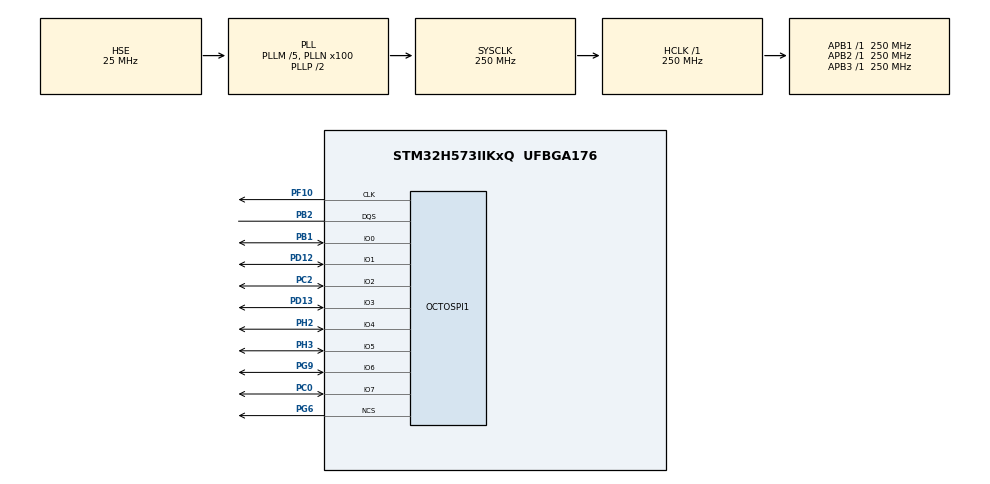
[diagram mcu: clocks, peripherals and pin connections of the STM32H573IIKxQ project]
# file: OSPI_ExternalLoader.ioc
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CORTEX_M33_NS.userName=CORTEX_M33
Mcu.Family=STM32H5
Mcu.Name=STM32H573IIKxQ
Mcu.Package=UFBGA176
NVIC.OCTOSPI1_IRQn=true\:0\:0\:false\:false\:true\:true\:true\:true
NVIC.PriorityGroup=NVIC_PRIORITYGROUP_4
OCTOSPI1.ChipSelectHighTimeCycle=1
OCTOSPI1.ClockMode=HAL_XSPI_CLOCK_MODE_0
OCTOSPI1.ClockPrescaler=1
OCTOSPI1.DelayHoldQuarterCycle=HAL_XSPI_DHQC_ENABLE
OCTOSPI1.FifoThresholdByte=4
OCTOSPI1.MemorySize=HAL_XSPI_SIZE_8MB
OCTOSPI1.MemoryType=HAL_XSPI_MEMTYPE_MACRONIX
OCTOSPI1.WrapSize=HAL_XSPI_WRAP_NOT_SUPPORTED
PB1.GPIO_Speed_High_Default=GPIO_SPEED_FREQ_HIGH
PB1.Mode=OCTOSPI1_IO_Octo
PB1.Signal=OCTOSPI1_IO0
PB2.GPIO_Speed_High_Default=GPIO_SPEED_FREQ_HIGH
PB2.Mode=octods_mode
PB2.Signal=OCTOSPI1_DQS
PC0.GPIO_Speed_High_Default=GPIO_SPEED_FREQ_HIGH
PC0.Mode=OCTOSPI1_IO_Octo
PC0.Signal=OCTOSPI1_IO7
PC2.GPIO_Speed_High_Default=GPIO_SPEED_FREQ_HIGH
PC2.Mode=OCTOSPI1_IO_Octo
PC2.Signal=OCTOSPI1_IO2
PD12.GPIO_Speed_High_Default=GPIO_SPEED_FREQ_HIGH
PD12.Mode=OCTOSPI1_IO_Octo
PD12.Signal=OCTOSPI1_IO1
PD13.GPIO_Speed_High_Default=GPIO_SPEED_FREQ_HIGH
PD13.Mode=OCTOSPI1_IO_Octo
PD13.Signal=OCTOSPI1_IO3
PF10.GPIO_Speed_High_Default=GPIO_SPEED_FREQ_HIGH
PF10.Mode=octods_mode
PF10.Signal=OCTOSPI1_CLK
PG6.GPIO_Speed_High_Default=GPIO_SPEED_FREQ_HIGH
PG6.Mode=octods_mode
PG6.Signal=OCTOSPI1_NCS
PG9.GPIO_Speed_High_Default=GPIO_SPEED_FREQ_HIGH
PG9.Mode=OCTOSPI1_IO_Octo
PG9.Signal=OCTOSPI1_IO6
PH0-OSC_IN(PH0).Mode=HSE-DIG-External-Clock-Source
PH0-OSC_IN(PH0).Signal=RCC_OSC_IN
PH2.GPIO_Speed_High_Default=GPIO_SPEED_FREQ_HIGH
PH2.Mode=OCTOSPI1_IO_Octo
PH2.Signal=OCTOSPI1_IO4
PH3.GPIO_Speed_High_Default=GPIO_SPEED_FREQ_HIGH
PH3.Mode=OCTOSPI1_IO_Octo
PH3.Signal=OCTOSPI1_IO5
ProjectManager.HeapSize=0x200
ProjectManager.StackSize=0x400
ProjectManager.TargetToolchain=STM32CubeIDE
RCC.ADCFreq_Value=250000000
RCC.AHBFreq_Value=250000000
RCC.APB1Freq_Value=250000000
RCC.APB1TimFreq_Value=250000000
RCC.APB2Freq_Value=250000000
RCC.APB2TimFreq_Value=250000000
RCC.APB3Freq_Value=250000000
RCC.CSI_VALUE=4000000
RCC.CortexFreq_Value=250000000
RCC.EPOD_VALUE=25000000
RCC.HCLKFreq_Value=250000000
RCC.HSE_VALUE=25000000
RCC.HSI48_VALUE=48000000
RCC.HSIDiv=RCC_HSI_DIV1
RCC.HSI_VALUE=64000000
RCC.LSE_VALUE=32768
RCC.LSIRC_VALUE=32000
RCC.OCTOSPIMCLockSelection=RCC_OSPICLKSOURCE_PLL2R
RCC.PLL2M=8
RCC.PLL2N=45
RCC.PLL2Source=RCC_PLL2_SOURCE_HSI
RCC.PLLM=5
RCC.PLLN=100
RCC.PLLSourceVirtual=RCC_PLL1_SOURCE_HSE
RCC.SYSCLKFreq_VALUE=250000000
RCC.SYSCLKSource=RCC_SYSCLKSOURCE_PLLCLK
RCC.USBFreq_Value=48000000
RCC.VCOOutputFreq_Value=500000000
VP_ICACHE_VS_ICACHE.Mode=DefaultMode
VP_PWR_VS_SECSignals.Mode=Security/Privilege
board=STM32H573I-DK

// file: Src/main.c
/* USER CODE BEGIN Header */
/**
  ******************************************************************************
  * @file           : main.c
  * @brief          : Main program body
  ******************************************************************************
  * @attention
  *
  * Copyright (c) 2025 STMicroelectronics.
  * All rights reserved.
  *
  * This software is licensed under terms that can be found in the LICENSE file
  * in the root directory of this software component.
  * If no LICENSE file comes with this software, it is provided AS-IS.
  *
  ******************************************************************************
  */
/* USER CODE END Header */
#include "main.h"
#include "icache.h"
#include "octospi.h"
#include "gpio.h"

void SystemClock_Config(void);

int main(void)
{

  /* USER CODE BEGIN 1 */
    uint32_t var = 0;
  /* USER CODE END 1 */

  /* MCU Configuration--------------------------------------------------------*/

  /* Reset of all peripherals, Initializes the Flash interface and the Systick. */
  HAL_Init();

  /* Configure the system clock */
  SystemClock_Config();

  /* Initialize all configured peripherals */
  MX_GPIO_Init();
  MX_ICACHE_Init();
  MX_OCTOSPI1_Init();
  /* USER CODE BEGIN 2 */
  CSP_QUADSPI_Init();
      for (var = 0; var < MEMORY_SECTOR_SIZE; var++) {
          buffer_test[var] = (var & 0xFF);
      }
      for (var = 0; var < SECTORS_COUNT; var++) {
          if (CSP_QSPI_EraseSector(var * MEMORY_SECTOR_SIZE, (var + 1) * MEMORY_SECTOR_SIZE - 1) != HAL_OK) {
              while (1) {}
          }
          if (CSP_QSPI_WriteMemory(buffer_test, var * MEMORY_SECTOR_SIZE, sizeof(buffer_test)) != HAL_OK) {
              while (1) {}
          }
      }
      if (CSP_QSPI_EnableMemoryMappedMode() != HAL_OK) {
          while (1) {}
      }
      for (var = 0; var < SECTORS_COUNT; var++) {
          if (memcmp(buffer_test, (uint8_t*) (0x90000000 + var * MEMORY_SECTOR_SIZE), MEMORY_SECTOR_SIZE) != HAL_OK) {
              while (1) {}
          }
      }
  /* USER CODE END 2 */

  /* Infinite loop */
  while (1)
  {

  }
}

void SystemClock_Config(void)
{
  RCC_OscInitTypeDef RCC_OscInitStruct = {0};
  RCC_ClkInitTypeDef RCC_ClkInitStruct = {0};

  /** Configure the main internal regulator output voltage
  */
  __HAL_PWR_VOLTAGESCALING_CONFIG(PWR_REGULATOR_VOLTAGE_SCALE0);

  while(!__HAL_PWR_GET_FLAG(PWR_FLAG_VOSRDY)) {}

  /** Initializes the RCC Oscillators according to the specified parameters
  * in the RCC_OscInitTypeDef structure.
  */
  RCC_OscInitStruct.OscillatorType = RCC_OSCILLATORTYPE_HSI|RCC_OSCILLATORTYPE_HSE;
  RCC_OscInitStruct.HSEState = RCC_HSE_BYPASS_DIGITAL;
  RCC_OscInitStruct.HSIState = RCC_HSI_ON;
  RCC_OscInitStruct.HSIDiv = RCC_HSI_DIV1;
  RCC_OscInitStruct.HSICalibrationValue = RCC_HSICALIBRATION_DEFAULT;
  RCC_OscInitStruct.PLL.PLLState = RCC_PLL_ON;
  RCC_OscInitStruct.PLL.PLLSource = RCC_PLL1_SOURCE_HSE;
  RCC_OscInitStruct.PLL.PLLM = 5;
  RCC_OscInitStruct.PLL.PLLN = 100;
  RCC_OscInitStruct.PLL.PLLP = 2;
  RCC_OscInitStruct.PLL.PLLQ = 2;
  RCC_OscInitStruct.PLL.PLLR = 2;
  RCC_OscInitStruct.PLL.PLLRGE = RCC_PLL1_VCIRANGE_2;
  RCC_OscInitStruct.PLL.PLLVCOSEL = RCC_PLL1_VCORANGE_WIDE;
  RCC_OscInitStruct.PLL.PLLFRACN = 0;
  if (HAL_RCC_OscConfig(&RCC_OscInitStruct) != HAL_OK)
  {
    Error_Handler();
  }

  /** Initializes the CPU, AHB and APB buses clocks
  */
  RCC_ClkInitStruct.ClockType = RCC_CLOCKTYPE_HCLK|RCC_CLOCKTYPE_SYSCLK
                              |RCC_CLOCKTYPE_PCLK1|RCC_CLOCKTYPE_PCLK2
                              |RCC_CLOCKTYPE_PCLK3;
  RCC_ClkInitStruct.SYSCLKSource = RCC_SYSCLKSOURCE_PLLCLK;
  RCC_ClkInitStruct.AHBCLKDivider = RCC_SYSCLK_DIV1;
  RCC_ClkInitStruct.APB1CLKDivider = RCC_HCLK_DIV1;
  RCC_ClkInitStruct.APB2CLKDivider = RCC_HCLK_DIV1;
  RCC_ClkInitStruct.APB3CLKDivider = RCC_HCLK_DIV1;

  if (HAL_RCC_ClockConfig(&RCC_ClkInitStruct, FLASH_LATENCY_5) != HAL_OK)
  {
    Error_Handler();
  }

  /** Configure the programming delay
  */
  __HAL_FLASH_SET_PROGRAM_DELAY(FLASH_PROGRAMMING_DELAY_2);
}

void Error_Handler(void)
{
  __disable_irq();
  while (1)
  {
  }
}
